# STM32F429 register map
File version: 1.8
CPU: CM4 r0p1, little endian, MPU, FPU, 4 interrupt priority bits
Registers are 32-bit, read-write, reset 0x0 unless marked. A register's access mark holds for its fields unless they carry their own. Offsets are from the block's base; [hi:lo] are bit positions; lines under a group give offsets from that group; {n}, {i} and the like mark numbered series.

## Ethernet_PTP — Ethernet: Precision time protocol
Base 0x40028700
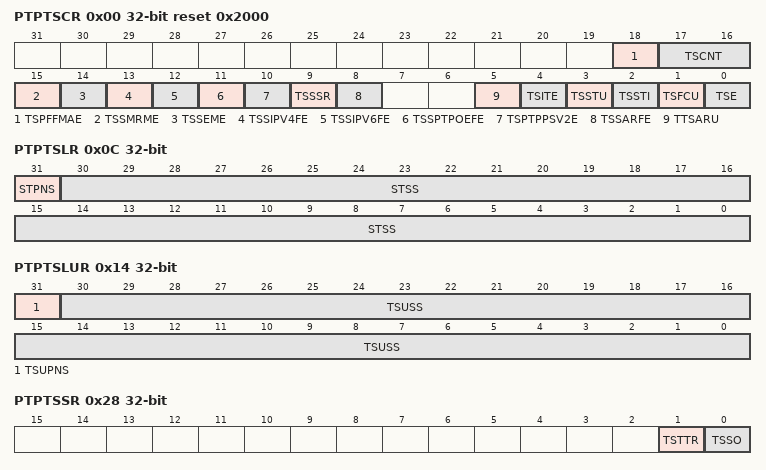
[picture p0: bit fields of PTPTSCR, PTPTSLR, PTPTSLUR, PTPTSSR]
0x00 PTPTSCR reset 0x2000 — Ethernet PTP time stamp control register
  [18] TSPFFMAE, [17:16] TSCNT, [15] TSSMRME, [14] TSSEME, [13] TSSIPV4FE, [12] TSSIPV6FE, [11] TSSPTPOEFE, [10] TSPTPPSV2E, [9] TSSSR, [8] TSSARFE, [5] TTSARU, [4] TSITE, [3] TSSTU, [2] TSSTI, [1] TSFCU, [0] TSE
0x04 PTPSSIR — Ethernet PTP subsecond increment register
  [7:0] STSSI
0x08 PTPTSHR ro — Ethernet PTP time stamp high register
  [31:0] STS
0x0C PTPTSLR ro — Ethernet PTP time stamp low register
  [31] STPNS, [30:0] STSS
0x10 PTPTSHUR — Ethernet PTP time stamp high update register
  [31:0] TSUS
0x14 PTPTSLUR — Ethernet PTP time stamp low update register
  [31] TSUPNS — TSUSS
  [30:0] TSUSS
0x18 PTPTSAR — Ethernet PTP time stamp addend register
  [31:0] TSA
0x1C PTPTTHR — Ethernet PTP target time high register
  [31:0] TTSH — 0
0x20 PTPTTLR — Ethernet PTP target time low register
  [31:0] TTSL
0x28 PTPTSSR ro — Ethernet PTP time stamp status register
  [1] TSTTR, [0] TSSO
0x2C PTPPPSCR ro — Ethernet PTP PPS control register
  [3:0] PPSFREQ rw — PPS frequency selection
    0=Hz_1 (1 Hz with a pulse width of 125 ms for binary rollover and of 100 ms for digital rollover); 1=Hz_2 (2 Hz with 50% duty cycle for binary rollover (digital rollover not recommended)); 2=Hz_4 (4 Hz with 50% duty cycle for binary rollover (digital rollover not recommended)); 3=Hz_8 (8 Hz with 50% duty cycle for binary rollover (digital rollover not recommended)); 4=Hz_16 (16 Hz with 50% duty cycle for binary rollover (digital rollover not recommended)); 5=Hz_32 (32 Hz with 50% duty cycle for binary rollover (digital rollover not recommended)); 6=Hz_64 (64 Hz with 50% duty cycle for binary rollover (digital rollover not recommended)); 7=Hz_128 (128 Hz with 50% duty cycle for binary rollover (digital rollover not recommended)); 8=Hz_256 (256 Hz with 50% duty cycle for binary rollover (digital rollover not recommended)); 9=Hz_512 (512 Hz with 50% duty cycle for binary rollover (digital rollover not recommended)); 10=Hz_1024 (1024 Hz with 50% duty cycle for binary rollover (digital rollover not recommended)); 11=Hz_2048 (2048 Hz with 50% duty cycle for binary rollover (digital rollover not recommended)); 12=Hz_4096 (4096 Hz with 50% duty cycle for binary rollover (digital rollover not recommended)); 13=Hz_8192 (8192 Hz with 50% duty cycle for binary rollover (digital rollover not recommended)); 14=Hz_16384 (16384 Hz with 50% duty cycle for binary rollover (digital rollover not recommended)); 15=Hz_32768 (32768 Hz with 50% duty cycle for binary rollover (digital rollover not recommended))

## CRC — Cryptographic processor
Base 0x40023000
0x00 DR reset 0xFFFFFFFF — Data register
  [31:0] DR — Data Register
0x04 IDR — Independent Data register
  [7:0] IDR
0x08 CR wo — Control register
  [0] RESET — Control regidter
    1=Resets the CRC calculation unit and sets the data register to 0xFFFF FFFF

## OTG_FS_HOST — USB on the go full speed
Base 0x50000400
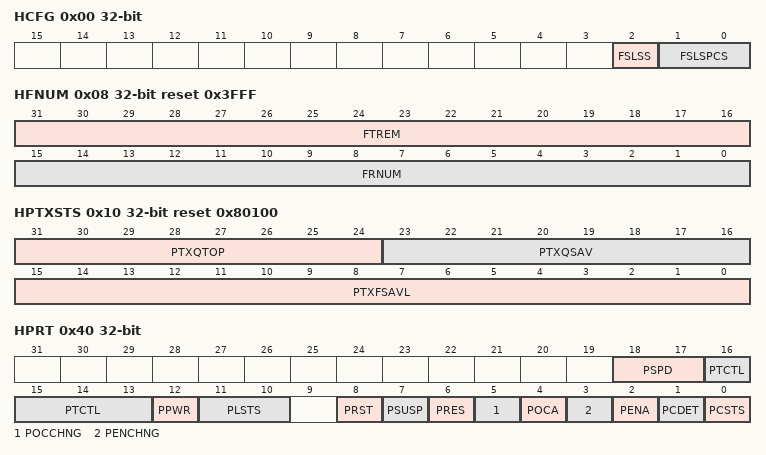
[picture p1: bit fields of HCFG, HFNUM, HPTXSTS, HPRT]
0x00 HCFG — OTG_FS host configuration register (OTG_FS_HCFG)
  [2] FSLSS — FS- and LS-only support
  [1:0] FSLSPCS — FS/LS PHY clock select
0x04 HFIR reset 0xEA60 — OTG_FS Host frame interval register
  [15:0] FRIVL — Frame interval
0x08 HFNUM ro reset 0x3FFF — OTG_FS host frame number/frame time remaining register (OTG_FS_HFNUM)
  [31:16] FTREM — Frame time remaining
  [15:0] FRNUM — Frame number
0x10 HPTXSTS access per field reset 0x80100 — OTG_FS_Host periodic transmit FIFO/queue status register (OTG_FS_HPTXSTS)
  [31:24] PTXQTOP ro — Top of the periodic transmit request queue
  [23:16] PTXQSAV ro — Periodic transmit request queue space available
  [15:0] PTXFSAVL rw — Periodic transmit data FIFO space available
0x14 HAINT ro — OTG_FS Host all channels interrupt register
  [15:0] HAINT — Channel interrupts
0x18 HAINTMSK — OTG_FS host all channels interrupt mask register
  [15:0] HAINTM — Channel interrupt mask
0x40 HPRT access per field — OTG_FS host port control and status register (OTG_FS_HPRT)
  [18:17] PSPD ro — Port speed
  [16:13] PTCTL rw — Port test control
  [12] PPWR rw — Port power
  [11:10] PLSTS ro — Port line status
  [8] PRST rw — Port reset
  [7] PSUSP rw — Port suspend
  [6] PRES rw — Port resume
  [5] POCCHNG rw — Port overcurrent change
  [4] POCA ro — Port overcurrent active
  [3] PENCHNG rw — Port enable/disable change
  [2] PENA rw — Port enable
  [1] PCDET rw — Port connect detected
  [0] PCSTS ro — Port connect status
{0x100+0x20*i} HC{i} (i=0..11) group — Host channel
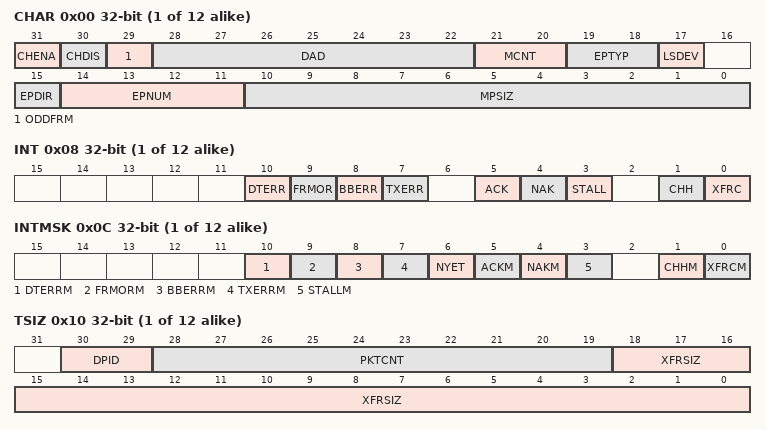
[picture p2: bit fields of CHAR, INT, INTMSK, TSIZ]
  0x00 CHAR — OTG_FS host channel-0 characteristics register (OTG_FS_HCCHAR0)
    [31] CHENA — Channel enable
    [30] CHDIS — Channel disable
    [29] ODDFRM — Odd frame
    [28:22] DAD — Device address
    [21:20] MCNT — Multicount
    [19:18] EPTYP — Endpoint type
    [17] LSDEV — Low-speed device
    [15] EPDIR — Endpoint direction
    [14:11] EPNUM — Endpoint number
    [10:0] MPSIZ — Maximum packet size
  0x08 INT — OTG_FS host channel-0 interrupt register (OTG_FS_HCINT0)
    [10] DTERR — Data toggle error
    [9] FRMOR — Frame overrun
    [8] BBERR — Babble error
    [7] TXERR — Transaction error
    [5] ACK — ACK response received/transmitted interrupt
    [4] NAK — NAK response received interrupt
    [3] STALL — STALL response received interrupt
    [1] CHH — Channel halted
    [0] XFRC — Transfer completed
  0x0C INTMSK — OTG_FS host channel-0 mask register (OTG_FS_HCINTMSK0)
    [10] DTERRM — Data toggle error mask
    [9] FRMORM — Frame overrun mask
    [8] BBERRM — Babble error mask
    [7] TXERRM — Transaction error mask
    [6] NYET — response received interrupt mask
    [5] ACKM — ACK response received/transmitted interrupt mask
    [4] NAKM — NAK response received interrupt mask
    [3] STALLM — STALL response received interrupt mask
    [1] CHHM — Channel halted mask
    [0] XFRCM — Transfer completed mask
  0x10 TSIZ — OTG_FS host channel-0 transfer size register
    [30:29] DPID — Data PID
    [28:19] PKTCNT — Packet count
    [18:0] XFRSIZ — Transfer size
